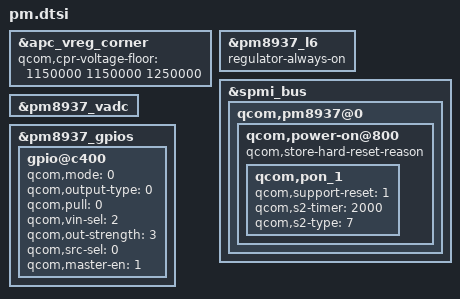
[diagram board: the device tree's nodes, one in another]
&apc_vreg_corner {
	qcom,cpr-voltage-floor = <1150000 1150000 1250000>;
};

&pm8937_l6 {
	regulator-always-on;
};

&spmi_bus {
	qcom,pm8937@0 {
		qcom,power-on@800 {
			qcom,store-hard-reset-reason;
			qcom,pon_1 {
				qcom,support-reset = <1>;
				qcom,s2-timer = <2000>;
				qcom,s2-type = <7>;
			};
		};
	};
};

&pm8937_vadc {
	/delete-node/ chan@11;
};

&pm8937_gpios {
	gpio@c400 {
		qcom,mode = <0>;
		qcom,output-type = <0>;
		qcom,pull = <0>;
		qcom,vin-sel = <2>;
		qcom,out-strength = <3>;
		qcom,src-sel = <0>;
		qcom,master-en = <1>;
		status = "okay";
	};
};
